# R7FA6T2BD register map
Vendor: Renesas Electronics Corporation; Series: RA6; File version: 1.40.00
CPU: CM33 r0p4, little endian, MPU, FPU, VTOR, 4 interrupt priority bits, 96 interrupts
Registers are 32-bit, read-write, reset 0x0 unless marked. A register's access mark holds for its fields unless they carry their own. Offsets are from the block's base; [hi:lo] are bit positions; {n}, {i} and the like mark numbered series.

## TFU — Trigonometric Function Unit
Base 0x40021000
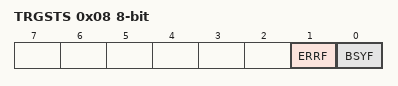
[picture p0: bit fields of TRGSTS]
0x08 TRGSTS 8-bit ro — Trigonometric Status Register
  [1] ERRF — Input error flag
  [0] BSYF — Calculation in progress flag
0x10 SCDT0 — Sine Cosine Data Register 0
  [31:0] SCDT0 — Sine Cosine Data Register 0 (single,precision floating,point)
0x14 SCDT1 — Sine Cosine Data Register 1
  [31:0] SCDT1 — Sine Cosine Data Register 1 (single,precision floating,point)
0x18 ATDT0 — Arctangent Data Register 0
  [31:0] ATDT0 — Arctangent Data Register 0 (single,precision floating,point)
0x1C ATDT1 — Arctangent Data Register 1
  [31:0] ATDT1 — Arctangent Data Register 1 (single,precision floating,point)

## ELC_B — Event Link Controller
Base 0x40082000
0x00 ELCR 8-bit — Event Link Controller Register
  [7] ELCON — All Event Link Enable
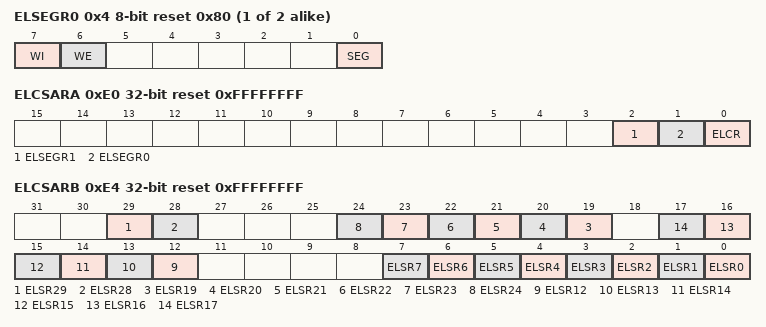
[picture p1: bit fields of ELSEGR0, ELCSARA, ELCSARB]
{0x4+4i} ELSEGR{i} (i=0..1) 8-bit reset 0x80 — Event Link Software Event Generation Register {i}
  [7] WI wo — ELSEGR Register Write Disable
  [6] WE — SEG Bit Write Enable
  [0] SEG wo — Software Event Generation
{0x20+4i} ELSR{i} (i=0..7) 16-bit — Event Link Setting Register {i}
  [8:0] ELS — Event Link Select
{0x20+4i} ELSR{i}_1 (i=12..17) 16-bit — Event Link Setting Register {i}
  [8:0] ELS — Event Link Select
{0x20+4i} ELSR{i}_2 (i=19..24) 16-bit — Event Link Setting Register {i}
  [8:0] ELS — Event Link Select
{0x20+4i} ELSR{i}_3 (i=28..29) 16-bit — Event Link Setting Register {i}
  [8:0] ELS — Event Link Select
0xE0 ELCSARA reset 0xFFFFFFFF — Event Link Controller Security Attribution Register A
  [2] ELSEGR1 — Event Link Software Event Generation Register 1 Security Attribution
  [1] ELSEGR0 — Event Link Software Event Generation Register 0 Security Attribution
  [0] ELCR — Event Link Controller Register Security Attribution
0xE4 ELCSARB reset 0xFFFFFFFF — Event Link Controller Security Attribution Register B
  [29] ELSR29 — Event Link Setting Register n Security Attribution
  [28] ELSR28 — Event Link Setting Register n Security Attribution
  [n] ELSR{n} (n=19..24) — Event Link Setting Register n Security Attribution
  [n] ELSR{n} (n=12..17) — Event Link Setting Register n Security Attribution
  [n] ELSR{n} (n=0..7) — Event Link Setting Register n Security Attribution

## IWDT — Independent Watchdog Timer
Base 0x40083200
0x00 IWDTRR 8-bit reset 0xFF — IWDT Refresh Register
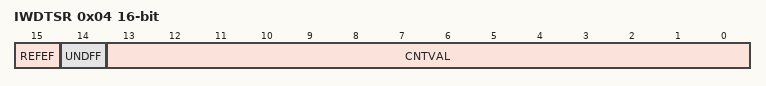
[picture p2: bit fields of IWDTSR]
0x04 IWDTSR 16-bit — IWDT Status Register
  [15] REFEF — Refresh Error Flag
  [14] UNDFF — Underflow Flag
  [13:0] CNTVAL ro — Down,counter Value

## WDT — Watchdog Timer
Base 0x40083400
0x00 WDTRR 8-bit reset 0xFF — WDT Refresh Register
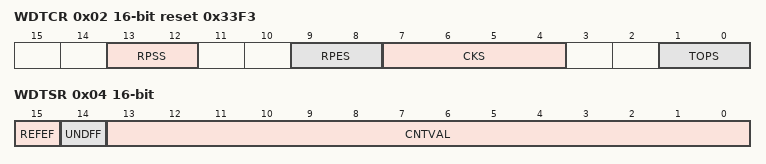
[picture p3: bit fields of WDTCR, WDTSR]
0x02 WDTCR 16-bit reset 0x33F3 — WDT Control Register
  [13:12] RPSS — Window Start Position Select
  [9:8] RPES — Window End Position Select
  [7:4] CKS — Clock Division Ratio Select
  [1:0] TOPS — Timeout Period Select
0x04 WDTSR 16-bit — WDT Status Register
  [15] REFEF — Refresh Error Flag
  [14] UNDFF — Underflow Flag
  [13:0] CNTVAL ro — Down,Counter Value
0x06 WDTRCR 8-bit reset 0x80 — WDT Reset Control Register
  [7] RSTIRQS — WDT Behavior Selection
0x08 WDTCSTPR 8-bit reset 0x80 — WDT Count Stop Control Register
  [7] SLCSTP — Sleep,Mode Count Stop Control Register

## CAC — Clock Frequency Accuracy Measurement Circuit
Base 0x40083600
0x00 CACR0 8-bit — CAC Control Register 0
  [0] CFME — Clock Frequency Measurement Enable
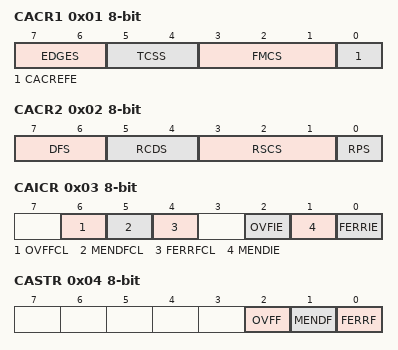
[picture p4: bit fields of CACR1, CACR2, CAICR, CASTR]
0x01 CACR1 8-bit — CAC Control Register 1
  [7:6] EDGES — Valid Edge Select
  [5:4] TCSS — Timer Count Clock Source Select
  [3:1] FMCS — Measurement Target Clock Select
  [0] CACREFE — CACREF Pin Input Enable
0x02 CACR2 8-bit — CAC Control Register 2
  [7:6] DFS — Digital Filter Select
  [5:4] RCDS — Measurement Reference Clock Frequency Division Ratio Select
  [3:1] RSCS — Measurement Reference Clock Select
  [0] RPS — Reference Signal Select
0x03 CAICR 8-bit — CAC Interrupt Control Register
  [6] OVFFCL wo — OVFF Clear
  [5] MENDFCL wo — MENDF Clear
  [4] FERRFCL wo — FERRF Clear
  [2] OVFIE — Overflow Interrupt Request Enable
  [1] MENDIE — Measurement End Interrupt Request Enable
  [0] FERRIE — Frequency Error Interrupt Request Enable
0x04 CASTR 8-bit ro — CAC Status Register
  [2] OVFF — Overflow Flag
  [1] MENDF — Measurement End Flag
  [0] FERRF — Frequency Error Flag
0x06 CAULVR 16-bit — CAC Upper,Limit Value Setting Register
0x08 CALLVR 16-bit — CAC Lower,Limit Value Setting Register
0x0A CACNTBR 16-bit ro — CAC Counter Buffer Register
